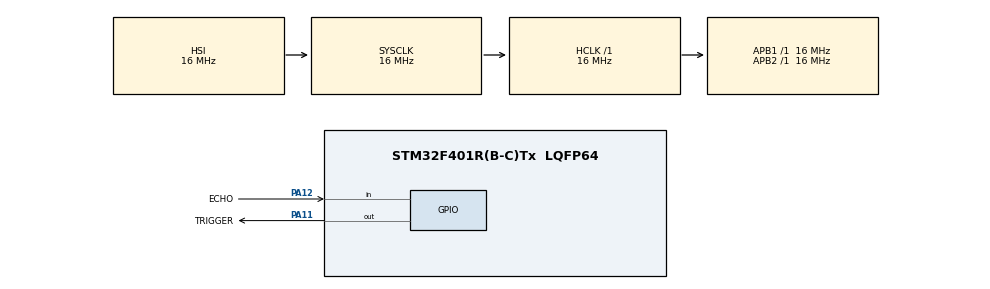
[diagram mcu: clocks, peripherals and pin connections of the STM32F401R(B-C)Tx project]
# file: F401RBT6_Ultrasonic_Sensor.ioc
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Mcu.Family=STM32F4
Mcu.Name=STM32F401R(B-C)Tx
Mcu.Package=LQFP64
NVIC.PriorityGroup=NVIC_PRIORITYGROUP_4
PA11.GPIO_Label=TRIGGER
PA11.Signal=GPIO_Output
PA12.GPIO_Label=ECHO
PA12.GPIO_PuPd=GPIO_NOPULL
PA12.Signal=GPIO_Input
PA13.Mode=Serial_Wire
PA13.Signal=SYS_JTMS-SWDIO
PA14.Mode=Serial_Wire
PA14.Signal=SYS_JTCK-SWCLK
PC14-OSC32_IN.Mode=LSE-External-Oscillator
PC14-OSC32_IN.Signal=RCC_OSC32_IN
PC15-OSC32_OUT.Mode=LSE-External-Oscillator
PC15-OSC32_OUT.Signal=RCC_OSC32_OUT
PH0\ -\ OSC_IN.Mode=HSE-External-Oscillator
PH0\ -\ OSC_IN.Signal=RCC_OSC_IN
PH1\ -\ OSC_OUT.Mode=HSE-External-Oscillator
PH1\ -\ OSC_OUT.Signal=RCC_OSC_OUT
ProjectManager.HeapSize=0x200
ProjectManager.StackSize=0x400
ProjectManager.TargetToolchain=STM32CubeIDE
RCC.AHBFreq_Value=16000000
RCC.APB1Freq_Value=16000000
RCC.APB2Freq_Value=16000000
RCC.CortexFreq_Value=16000000
RCC.HSE_VALUE=25000000
RCC.HSI_VALUE=16000000
RCC.SYSCLKFreq_VALUE=16000000
RCC.VCOOutputFreq_Value=192000000
TIM1.AutoReloadPreload=TIM_AUTORELOAD_PRELOAD_DISABLE
TIM1.Prescaler=83
VP_TIM1_VS_ClockSourceINT.Mode=Internal
board=custom

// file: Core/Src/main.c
/* USER CODE BEGIN Header */
/**
  ******************************************************************************
  * @file           : main.c
  * @brief          : Main program body
  ******************************************************************************
  * @attention
  *
  * Copyright (c) 2025 STMicroelectronics.
  * All rights reserved.
  *
  * This software is licensed under terms that can be found in the LICENSE file
  * in the root directory of this software component.
  * If no LICENSE file comes with this software, it is provided AS-IS.
  *
  ******************************************************************************
  */
/* USER CODE END Header */
#include "main.h"

TIM_HandleTypeDef htim1;

void SystemClock_Config(void);
static void MX_GPIO_Init(void);
static void MX_TIM1_Init(void);
/* USER CODE BEGIN PFP */
void delay_us(uint32_t us)
{
    __HAL_TIM_SET_COUNTER(&htim1, 0);
    while (__HAL_TIM_GET_COUNTER(&htim1) < us);
}
/* USER CODE END PFP */

/* USER CODE BEGIN 0 */
float distance_cm=0;
/* USER CODE END 0 */

int main(void)
{

  /* MCU Configuration--------------------------------------------------------*/

  /* Reset of all peripherals, Initializes the Flash interface and the Systick. */
  HAL_Init();

  /* Configure the system clock */
  SystemClock_Config();

  /* Initialize all configured peripherals */
  MX_GPIO_Init();
  MX_TIM1_Init();
  /* USER CODE BEGIN 2 */
  HAL_TIM_Base_Start(&htim1);  // Start microsecond timer

      uint32_t start, end, duration;

  /* USER CODE END 2 */

  /* Infinite loop */
  while (1)
  {
	  HAL_GPIO_WritePin(GPIOA, GPIO_PIN_11, GPIO_PIN_RESET);
	         delay_us(2);
	         HAL_GPIO_WritePin(GPIOA, GPIO_PIN_11, GPIO_PIN_SET);
	         delay_us(10);
	         HAL_GPIO_WritePin(GPIOA, GPIO_PIN_11, GPIO_PIN_RESET);

	         // Wait for Echo (PA12) to go HIGH
	         while (HAL_GPIO_ReadPin(GPIOA, GPIO_PIN_12) == GPIO_PIN_RESET);

	         start = __HAL_TIM_GET_COUNTER(&htim1);

	         // Wait for Echo to go LOW
	         while (HAL_GPIO_ReadPin(GPIOA, GPIO_PIN_12) == GPIO_PIN_SET);

	         end = __HAL_TIM_GET_COUNTER(&htim1);

	         // Calculate pulse duration
	         duration = (end >= start) ? (end - start) : ((0xFFFF - start) + end);

	         // Convert to distance in cm
	         distance_cm = (duration * 0.0343f) / 2.0f;

	         // Distance now stored in distance_cm (float)
	         // You can use it here (store, compare, control)

	         HAL_Delay(500);  // Wait before next reading
  }
}

void SystemClock_Config(void)
{
  RCC_OscInitTypeDef RCC_OscInitStruct = {0};
  RCC_ClkInitTypeDef RCC_ClkInitStruct = {0};

  /** Configure the main internal regulator output voltage
  */
  __HAL_RCC_PWR_CLK_ENABLE();
  __HAL_PWR_VOLTAGESCALING_CONFIG(PWR_REGULATOR_VOLTAGE_SCALE2);

  /** Initializes the RCC Oscillators according to the specified parameters
  * in the RCC_OscInitTypeDef structure.
  */
  RCC_OscInitStruct.OscillatorType = RCC_OSCILLATORTYPE_HSI;
  RCC_OscInitStruct.HSIState = RCC_HSI_ON;
  RCC_OscInitStruct.HSICalibrationValue = RCC_HSICALIBRATION_DEFAULT;
  RCC_OscInitStruct.PLL.PLLState = RCC_PLL_NONE;
  if (HAL_RCC_OscConfig(&RCC_OscInitStruct) != HAL_OK)
  {
    Error_Handler();
  }

  /** Initializes the CPU, AHB and APB buses clocks
  */
  RCC_ClkInitStruct.ClockType = RCC_CLOCKTYPE_HCLK|RCC_CLOCKTYPE_SYSCLK
                              |RCC_CLOCKTYPE_PCLK1|RCC_CLOCKTYPE_PCLK2;
  RCC_ClkInitStruct.SYSCLKSource = RCC_SYSCLKSOURCE_HSI;
  RCC_ClkInitStruct.AHBCLKDivider = RCC_SYSCLK_DIV1;
  RCC_ClkInitStruct.APB1CLKDivider = RCC_HCLK_DIV1;
  RCC_ClkInitStruct.APB2CLKDivider = RCC_HCLK_DIV1;

  if (HAL_RCC_ClockConfig(&RCC_ClkInitStruct, FLASH_LATENCY_0) != HAL_OK)
  {
    Error_Handler();
  }
}

static void MX_TIM1_Init(void)
{

  TIM_ClockConfigTypeDef sClockSourceConfig = {0};
  TIM_MasterConfigTypeDef sMasterConfig = {0};

  htim1.Instance = TIM1;
  htim1.Init.Prescaler = 83;
  htim1.Init.CounterMode = TIM_COUNTERMODE_UP;
  htim1.Init.Period = 65535;
  htim1.Init.ClockDivision = TIM_CLOCKDIVISION_DIV1;
  htim1.Init.RepetitionCounter = 0;
  htim1.Init.AutoReloadPreload = TIM_AUTORELOAD_PRELOAD_DISABLE;
  if (HAL_TIM_Base_Init(&htim1) != HAL_OK)
  {
    Error_Handler();
  }
  sClockSourceConfig.ClockSource = TIM_CLOCKSOURCE_INTERNAL;
  if (HAL_TIM_ConfigClockSource(&htim1, &sClockSourceConfig) != HAL_OK)
  {
    Error_Handler();
  }
  sMasterConfig.MasterOutputTrigger = TIM_TRGO_RESET;
  sMasterConfig.MasterSlaveMode = TIM_MASTERSLAVEMODE_DISABLE;
  if (HAL_TIMEx_MasterConfigSynchronization(&htim1, &sMasterConfig) != HAL_OK)
  {
    Error_Handler();
  }

}

static void MX_GPIO_Init(void)
{
  GPIO_InitTypeDef GPIO_InitStruct = {0};

  /* GPIO Ports Clock Enable */
  __HAL_RCC_GPIOC_CLK_ENABLE();
  __HAL_RCC_GPIOH_CLK_ENABLE();
  __HAL_RCC_GPIOA_CLK_ENABLE();

  /*Configure GPIO pin Output Level */
  HAL_GPIO_WritePin(TRIGGER_GPIO_Port, TRIGGER_Pin, GPIO_PIN_RESET);

  /*Configure GPIO pin : TRIGGER_Pin */
  GPIO_InitStruct.Pin = TRIGGER_Pin;
  GPIO_InitStruct.Mode = GPIO_MODE_OUTPUT_PP;
  GPIO_InitStruct.Pull = GPIO_NOPULL;
  GPIO_InitStruct.Speed = GPIO_SPEED_FREQ_LOW;
  HAL_GPIO_Init(TRIGGER_GPIO_Port, &GPIO_InitStruct);

  /*Configure GPIO pin : ECHO_Pin */
  GPIO_InitStruct.Pin = ECHO_Pin;
  GPIO_InitStruct.Mode = GPIO_MODE_INPUT;
  GPIO_InitStruct.Pull = GPIO_NOPULL;
  HAL_GPIO_Init(ECHO_GPIO_Port, &GPIO_InitStruct);

}

void Error_Handler(void)
{
  __disable_irq();
  while (1)
  {
  }
}
